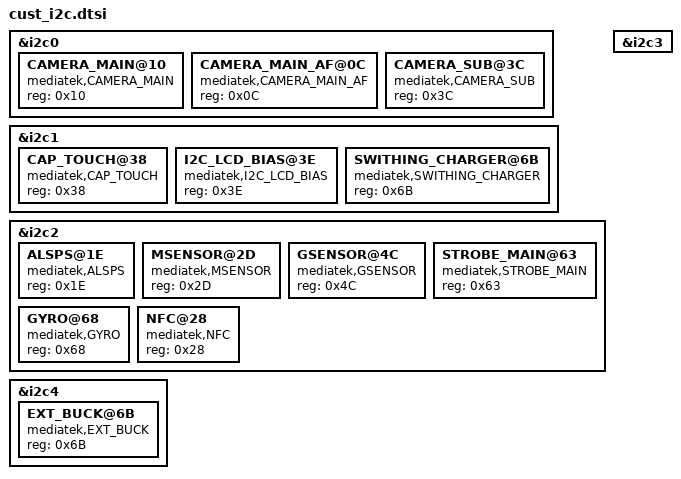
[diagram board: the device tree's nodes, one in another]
/*
 * Generated by MTK SP DrvGen Version 03.13.6 for MT6753. Copyright MediaTek Inc. (C) 2013.
 * Sun Sep 11 02:21:42 2016
 * Do Not Modify the File.
 *
 * M1612 note: this generated-layer file is NOT included in the DTS build
 * (only cust.dtsi is, via mt6753.dtsi). Kept in sync with the M1612 live DT
 * dump (/srv/forge/android/m5s/stock/m5s_dt/base/bus/i2c@1100x000) so the
 * DCT layer does not contradict cust.dtsi. m2note map (camera_sub@36,
 * I2C_LCD_BIAS@63 on i2c2, STROBE_MAIN@63 on i2c3, gsensor@6A, msensor@0D)
 * replaced by the live map.
 */

/*************************
 * I2C DTSI File
*************************/

&i2c0 {
	CAMERA_MAIN@10 {
		compatible = "mediatek,CAMERA_MAIN";
		reg = <0x10>;
	};

	CAMERA_MAIN_AF@0C {
		compatible = "mediatek,CAMERA_MAIN_AF";
		reg = <0x0C>;
	};

	CAMERA_SUB@3C {
		compatible = "mediatek,CAMERA_SUB";
		reg = <0x3C>;
	};

};

&i2c1 {
	CAP_TOUCH@38 {
		compatible = "mediatek,CAP_TOUCH";
		reg = <0x38>;
	};

	I2C_LCD_BIAS@3E {
		compatible = "mediatek,I2C_LCD_BIAS";
		reg = <0x3E>;
	};

	SWITHING_CHARGER@6B {
		compatible = "mediatek,SWITHING_CHARGER";
		reg = <0x6B>;
	};

};

&i2c2 {
	ALSPS@1E {
		compatible = "mediatek,ALSPS";
		reg = <0x1E>;
	};

	MSENSOR@2D {
		compatible = "mediatek,MSENSOR";
		reg = <0x2D>;
	};

	GSENSOR@4C {
		compatible = "mediatek,GSENSOR";
		reg = <0x4C>;
	};

	STROBE_MAIN@63 {
		compatible = "mediatek,STROBE_MAIN";
		reg = <0x63>;
	};

	GYRO@68 {
		compatible = "mediatek,GYRO";
		reg = <0x68>;
	};

	NFC@28 {
		compatible = "mediatek,NFC";
		reg = <0x28>;
	};

};

&i2c3 {
};

&i2c4 {
	EXT_BUCK@6B {
		compatible = "mediatek,EXT_BUCK";
		reg = <0x6B>;
	};

};
